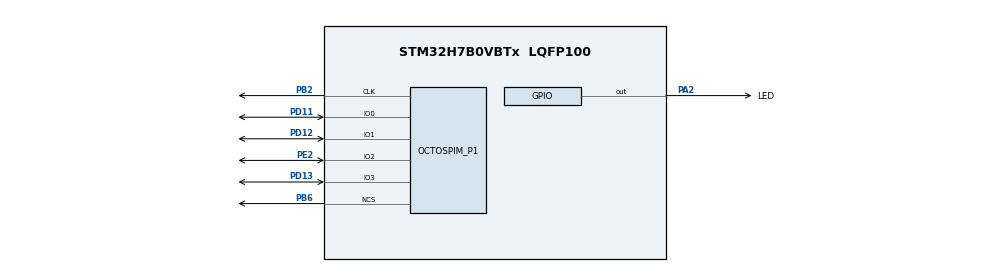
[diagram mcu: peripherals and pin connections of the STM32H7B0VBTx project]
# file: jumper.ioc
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Mcu.Family=STM32H7
Mcu.Name=STM32H7B0VBTx
Mcu.Package=LQFP100
NVIC.PriorityGroup=NVIC_PRIORITYGROUP_4
PA13.Mode=Serial_Wire
PA13.Signal=DEBUG_JTMS-SWDIO
PA14.Mode=Serial_Wire
PA14.Signal=DEBUG_JTCK-SWCLK
PA2.GPIO_Label=LED
PA2.Signal=GPIO_Output
PB2.Mode=O1_P1_CLK
PB2.Signal=OCTOSPIM_P1_CLK
PB6.Mode=OCTOSPI1_Port1_NCS
PB6.Signal=OCTOSPIM_P1_NCS
PD11.Mode=OCTOSPI1_IOL_Port1L
PD11.Signal=OCTOSPIM_P1_IO0
PD12.Mode=OCTOSPI1_IOL_Port1L
PD12.Signal=OCTOSPIM_P1_IO1
PD13.Mode=OCTOSPI1_IOL_Port1L
PD13.Signal=OCTOSPIM_P1_IO3
PE2.Mode=OCTOSPI1_IOL_Port1L
PE2.Signal=OCTOSPIM_P1_IO2
PH0-OSC_IN.Mode=HSE-External-Oscillator
PH0-OSC_IN.Signal=RCC_OSC_IN
PH1-OSC_OUT.Mode=HSE-External-Oscillator
PH1-OSC_OUT.Signal=RCC_OSC_OUT
ProjectManager.HeapSize=0x200
ProjectManager.StackSize=0x400
ProjectManager.TargetToolchain=STM32CubeIDE
RCC.ADCFreq_Value=32250000
RCC.APB1Freq_Value=140000000
RCC.APB2Freq_Value=140000000
RCC.APB3Freq_Value=140000000
RCC.APB4Freq_Value=140000000
RCC.CDPPRE=RCC_APB3_DIV2
RCC.CDPPRE1=RCC_APB1_DIV2
RCC.CDPPRE2=RCC_APB2_DIV2
RCC.CortexFreq_Value=280000000
RCC.DIVM1=1
RCC.DIVN1=35
RCC.HCLKFreq_Value=280000000
RCC.HSE_VALUE=16000000
RCC.PLLFRACN=0
RCC.PLLSourceVirtual=RCC_PLLSOURCE_HSE
RCC.SRDPPRE=RCC_APB4_DIV2
RCC.SYSCLKFreq_VALUE=280000000
RCC.SYSCLKSource=RCC_SYSCLKSOURCE_PLLCLK
RCC.USBFreq_Value=280000000
VP_OCTOSPI1_VS_quad.Mode=quad_mode
board=custom

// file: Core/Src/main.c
/* USER CODE BEGIN Header */
/**
 ******************************************************************************
 * @file           : main.c
 * @brief          : Main program body
 ******************************************************************************
 * @attention
 *
 * Copyright (c) 2024 STMicroelectronics.
 * All rights reserved.
 *
 * This software is licensed under terms that can be found in the LICENSE file
 * in the root directory of this software component.
 * If no LICENSE file comes with this software, it is provided AS-IS.
 *
 ******************************************************************************
 */
/* USER CODE END Header */
#include "main.h"
#include "octospi.h"
#include "gpio.h"

/* USER CODE BEGIN Includes */
#include "../../External_flash/ospi_w25q64.h"
/* USER CODE END Includes */

/* USER CODE BEGIN PTD */

////
#define APPLICATION_ADDRESS 0x90000000U
typedef void (*pFunction)(void);
pFunction JumpToApplication;
/* USER CODE END PTD */

void SystemClock_Config(void);

int main(void)
{

  /* MCU Configuration--------------------------------------------------------*/

  /* Reset of all peripherals, Initializes the Flash interface and the Systick. */
  HAL_Init();

  /* Configure the system clock */
  SystemClock_Config();

  /* Initialize all configured peripherals */
  MX_GPIO_Init();
  MX_OCTOSPI1_Init();
  /* USER CODE BEGIN 2 */
	//
	HAL_GPIO_WritePin(LED_GPIO_Port, LED_Pin, GPIO_PIN_SET);
	HAL_Delay(1000);
	HAL_GPIO_WritePin(LED_GPIO_Port, LED_Pin, GPIO_PIN_RESET);
	//

	//if(OSPI_W25Qxx_Test()){while(1);}

	OSPI_W25Qxx_Init();
	OSPI_W25Qxx_MemoryMappedMode();
	SysTick->CTRL = 0;
	JumpToApplication = (pFunction) (*(__IO uint32_t*) (APPLICATION_ADDRESS + 4));
	__set_MSP(*(__IO uint32_t*) APPLICATION_ADDRESS);
	JumpToApplication();

  /* USER CODE END 2 */

  /* Infinite loop */
	while (1)
	{

	}
}

void SystemClock_Config(void)
{
  RCC_OscInitTypeDef RCC_OscInitStruct = {0};
  RCC_ClkInitTypeDef RCC_ClkInitStruct = {0};

  /*AXI clock gating */
  RCC->CKGAENR = 0xFFFFFFFF;

  /** Supply configuration update enable
  */
  HAL_PWREx_ConfigSupply(PWR_LDO_SUPPLY);

  /** Configure the main internal regulator output voltage
  */
  __HAL_PWR_VOLTAGESCALING_CONFIG(PWR_REGULATOR_VOLTAGE_SCALE0);

  while(!__HAL_PWR_GET_FLAG(PWR_FLAG_VOSRDY)) {}

  /** Initializes the RCC Oscillators according to the specified parameters
  * in the RCC_OscInitTypeDef structure.
  */
  RCC_OscInitStruct.OscillatorType = RCC_OSCILLATORTYPE_HSE;
  RCC_OscInitStruct.HSEState = RCC_HSE_ON;
  RCC_OscInitStruct.PLL.PLLState = RCC_PLL_ON;
  RCC_OscInitStruct.PLL.PLLSource = RCC_PLLSOURCE_HSE;
  RCC_OscInitStruct.PLL.PLLM = 1;
  RCC_OscInitStruct.PLL.PLLN = 35;
  RCC_OscInitStruct.PLL.PLLP = 2;
  RCC_OscInitStruct.PLL.PLLQ = 2;
  RCC_OscInitStruct.PLL.PLLR = 2;
  RCC_OscInitStruct.PLL.PLLRGE = RCC_PLL1VCIRANGE_3;
  RCC_OscInitStruct.PLL.PLLVCOSEL = RCC_PLL1VCOWIDE;
  RCC_OscInitStruct.PLL.PLLFRACN = 0;
  if (HAL_RCC_OscConfig(&RCC_OscInitStruct) != HAL_OK)
  {
    Error_Handler();
  }

  /** Initializes the CPU, AHB and APB buses clocks
  */
  RCC_ClkInitStruct.ClockType = RCC_CLOCKTYPE_HCLK|RCC_CLOCKTYPE_SYSCLK
                              |RCC_CLOCKTYPE_PCLK1|RCC_CLOCKTYPE_PCLK2
                              |RCC_CLOCKTYPE_D3PCLK1|RCC_CLOCKTYPE_D1PCLK1;
  RCC_ClkInitStruct.SYSCLKSource = RCC_SYSCLKSOURCE_PLLCLK;
  RCC_ClkInitStruct.SYSCLKDivider = RCC_SYSCLK_DIV1;
  RCC_ClkInitStruct.AHBCLKDivider = RCC_HCLK_DIV1;
  RCC_ClkInitStruct.APB3CLKDivider = RCC_APB3_DIV2;
  RCC_ClkInitStruct.APB1CLKDivider = RCC_APB1_DIV2;
  RCC_ClkInitStruct.APB2CLKDivider = RCC_APB2_DIV2;
  RCC_ClkInitStruct.APB4CLKDivider = RCC_APB4_DIV2;

  if (HAL_RCC_ClockConfig(&RCC_ClkInitStruct, FLASH_LATENCY_6) != HAL_OK)
  {
    Error_Handler();
  }
}

void Error_Handler(void)
{
	__disable_irq();
	while (1)
	{
	}
}
